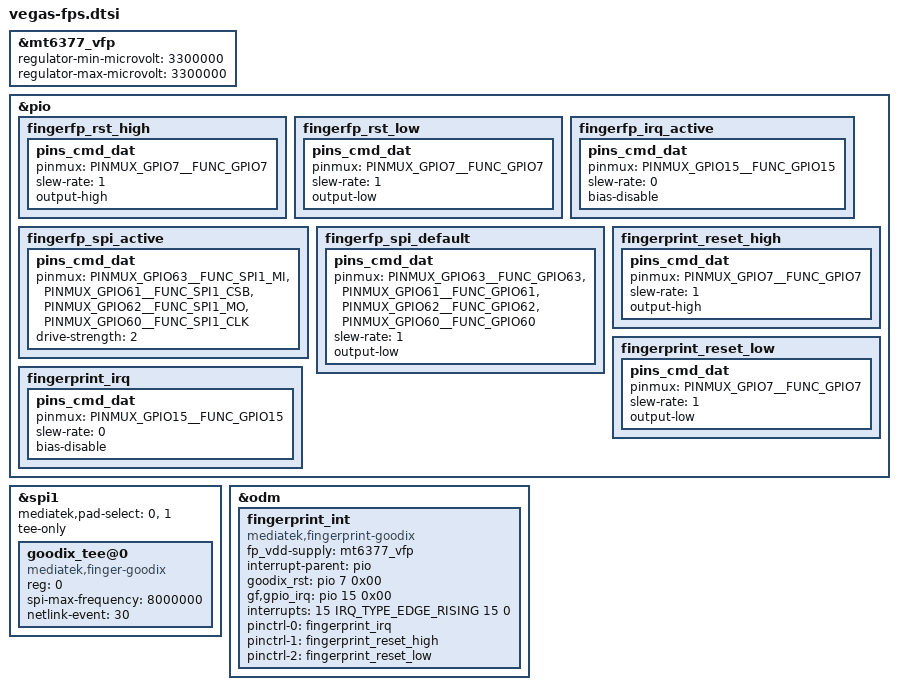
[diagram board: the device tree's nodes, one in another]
&mt6377_vfp {
	regulator-min-microvolt = <3300000>;
	regulator-max-microvolt = <3300000>;
//	regulator-always-on;
};

&pio {

        fingerfp_rst_high: fingerfp_rst_high {
                pins_cmd_dat {
                        pinmux = <PINMUX_GPIO7__FUNC_GPIO7>;
                        slew-rate = <1>;
                        output-high;
                };
        };

        fingerfp_rst_low: fingerfp_rst_low {
                pins_cmd_dat {
                        pinmux = <PINMUX_GPIO7__FUNC_GPIO7>;
                        slew-rate = <1>;
                        output-low;
                };
        };

        fingerfp_irq_active: fingerfp_irq_active {
                pins_cmd_dat {
                        pinmux = <PINMUX_GPIO15__FUNC_GPIO15>;
                        slew-rate = <0>;
                        bias-disable;
                };
        };

        fingerfp_spi_active: fingerfp_spi_active {
                pins_cmd_dat {
                        pinmux = <PINMUX_GPIO63__FUNC_SPI1_MI>, <PINMUX_GPIO61__FUNC_SPI1_CSB>, <PINMUX_GPIO62__FUNC_SPI1_MO>, <PINMUX_GPIO60__FUNC_SPI1_CLK>;
                        drive-strength = <2>;
                };
        };

        fingerfp_spi_default: fingerfp_spi_default {
                pins_cmd_dat {
                        pinmux = <PINMUX_GPIO63__FUNC_GPIO63>, <PINMUX_GPIO61__FUNC_GPIO61>, <PINMUX_GPIO62__FUNC_GPIO62>, <PINMUX_GPIO60__FUNC_GPIO60>;
                        slew-rate = <1>;
                        output-low;
                };
        };
        fingerprint_irq: fingerprint_irq {
                pins_cmd_dat {
                        pinmux = <PINMUX_GPIO15__FUNC_GPIO15>;
                        slew-rate = <0>;
                        bias-disable;
                };
        };

        fingerprint_reset_high: fingerprint_reset_high {
                pins_cmd_dat {
                        pinmux = <PINMUX_GPIO7__FUNC_GPIO7>;
                        slew-rate = <1>;
                        output-high;
                };
        };

        fingerprint_reset_low: fingerprint_reset_low {
                pins_cmd_dat {
                        pinmux = <PINMUX_GPIO7__FUNC_GPIO7>;
                        slew-rate = <1>;
                        output-low;
                };
        };
 };

/* FINGERPRINT start */
&spi1 {
        status = "okay";
        mediatek,pad-select = <0>, <1>;
        tee-only;

        goodix_tee@0 {
                compatible = "mediatek,finger-goodix";
                reg = <0>;
                spi-max-frequency = <8000000>;
                netlink-event = <30>;
                status = "okay";
        };
/*
        chipone_tee@1 {
                status = "okay";
                compatible = "mediatek,finger-chipone";
                reg = <1>;
                spi-max-frequency = <10000000>;
                netlink-event = <30>;
        };
*/
};

&odm {

        fingerprint_int: fingerprint_int {
                compatible = "mediatek,fingerprint-goodix";
                fp_vdd-supply = <&mt6377_vfp>;
                interrupt-parent = <&pio>;
                goodix_rst = <&pio 7 0x00>;
                gf,gpio_irq = <&pio 15 0x00>;
                interrupts = <15 IRQ_TYPE_EDGE_RISING 15 0>;
                pinctrl-names = "fingerprint_irq", "fingerprint_reset_high", "fingerprint_reset_low";
                pinctrl-0 = <&fingerprint_irq>;
                pinctrl-1 = <&fingerprint_reset_high>;
                pinctrl-2 = <&fingerprint_reset_low>;
                status = "okay";
        };
};

/*
&spi1 {
	status = "okay";
	#address-cells = <1>;
	#size-cells = <0>;
	tee-only;
	goodix@0 {
		compatible = "mediatek,finger-goodix";
		reg = <0>;
		spi-max-frequency = <1000000>;
		status = "okay";
	};
};

&pio {
	fpc_fp_pins_spi: state_spi_mode {
		pins_cmd_dat {
			pinmux = <PINMUX_GPIO61__FUNC_SPI1_CSB>,
					<PINMUX_GPIO60__FUNC_SPI1_CLK>,
					<PINMUX_GPIO63__FUNC_SPI1_MI>,
					<PINMUX_GPIO62__FUNC_SPI1_MO>;
			drive-strength = <4>;
		};
	};
};

&odm {
	goodix_fp: goodix_fp {
		compatible = "mediatek,fingerprint-goodix";
		interrupt-parent = <&pio>;
		interrupts = <15 IRQ_TYPE_EDGE_RISING 15 0>;
		fp_vdd-supply = <&mt6377_vfp>;
		goodix_rst = <&pio 7 0x00>;
		gf,gpio_irq = <&pio 15 0x00>;
		status = "okay";
	};
};
*/
